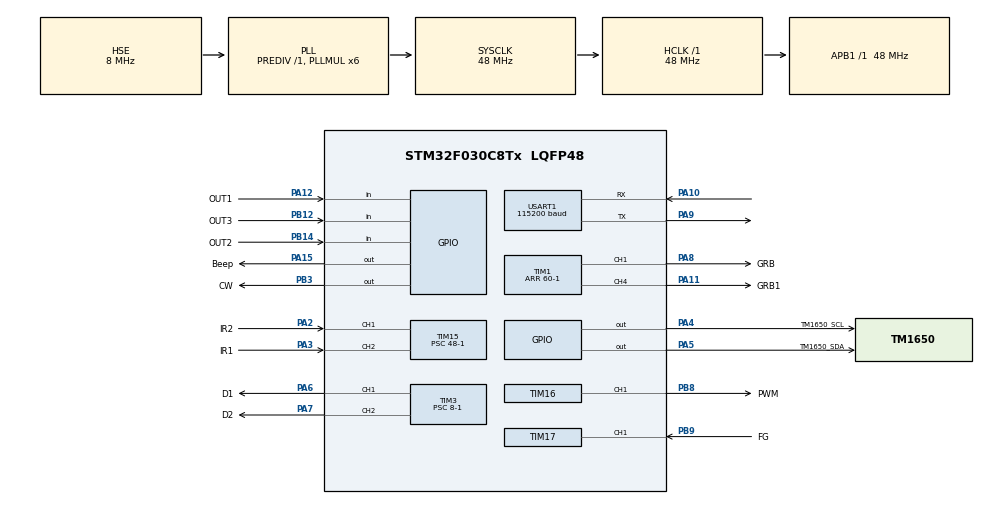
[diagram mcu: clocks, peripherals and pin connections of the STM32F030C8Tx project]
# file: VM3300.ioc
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Dma.Request0=TIM1_CH1
Dma.Request1=TIM1_CH4/TRIG/COM
Dma.TIM1_CH1.0.Direction=DMA_MEMORY_TO_PERIPH
Dma.TIM1_CH1.0.Instance=DMA1_Channel2
Dma.TIM1_CH1.0.MemDataAlignment=DMA_MDATAALIGN_HALFWORD
Dma.TIM1_CH1.0.MemInc=DMA_MINC_ENABLE
Dma.TIM1_CH1.0.Mode=DMA_NORMAL
Dma.TIM1_CH1.0.PeriphDataAlignment=DMA_PDATAALIGN_HALFWORD
Dma.TIM1_CH1.0.PeriphInc=DMA_PINC_DISABLE
Dma.TIM1_CH1.0.Priority=DMA_PRIORITY_MEDIUM
Dma.TIM1_CH4/TRIG/COM.1.Direction=DMA_MEMORY_TO_PERIPH
Dma.TIM1_CH4/TRIG/COM.1.Instance=DMA1_Channel4
Dma.TIM1_CH4/TRIG/COM.1.MemDataAlignment=DMA_MDATAALIGN_HALFWORD
Dma.TIM1_CH4/TRIG/COM.1.MemInc=DMA_MINC_ENABLE
Dma.TIM1_CH4/TRIG/COM.1.Mode=DMA_NORMAL
Dma.TIM1_CH4/TRIG/COM.1.PeriphDataAlignment=DMA_PDATAALIGN_HALFWORD
Dma.TIM1_CH4/TRIG/COM.1.PeriphInc=DMA_PINC_DISABLE
Dma.TIM1_CH4/TRIG/COM.1.Priority=DMA_PRIORITY_MEDIUM
Mcu.Family=STM32F0
Mcu.Name=STM32F030C8Tx
Mcu.Package=LQFP48
NVIC.DMA1_Channel2_3_IRQn=true\:0\:0\:false\:false\:true\:false\:true\:true
NVIC.DMA1_Channel4_5_IRQn=true\:0\:0\:false\:false\:true\:false\:true\:true
NVIC.TIM15_IRQn=true\:0\:0\:true\:false\:true\:true\:true\:true
NVIC.TIM17_IRQn=true\:0\:0\:false\:false\:true\:true\:true\:true
NVIC.TIM6_IRQn=true\:0\:0\:false\:false\:true\:true\:true\:true
NVIC.USART1_IRQn=true\:1\:0\:true\:false\:true\:true\:true\:true
PA10.Mode=Asynchronous
PA10.Signal=USART1_RX
PA11.GPIO_Label=GRB1
PA11.Signal=S_TIM1_CH4
PA12.GPIO_Label=OUT1
PA12.Signal=GPIO_Input
PA13.Mode=Serial_Wire
PA13.Signal=SYS_SWDIO
PA14.Mode=Serial_Wire
PA14.Signal=SYS_SWCLK
PA15.GPIO_Label=Beep
PA15.Signal=GPIO_Output
PA2.GPIO_Label=IR2
PA2.Signal=S_TIM15_CH1
PA3.GPIO_Label=IR1
PA3.Signal=S_TIM15_CH2
PA4.GPIO_Label=TM1650_SCL
PA4.GPIO_PuPd=GPIO_PULLUP
PA4.GPIO_Speed=GPIO_SPEED_FREQ_HIGH
PA4.PinState=GPIO_PIN_SET
PA4.Signal=GPIO_Output
PA5.GPIO_Label=TM1650_SDA
PA5.GPIO_PuPd=GPIO_PULLUP
PA5.GPIO_Speed=GPIO_SPEED_FREQ_HIGH
PA5.PinState=GPIO_PIN_SET
PA5.Signal=GPIO_Output
PA6.GPIO_Label=D1
PA6.Signal=S_TIM3_CH1
PA7.GPIO_Label=D2
PA7.Signal=S_TIM3_CH2
PA8.GPIO_Label=GRB
PA8.Signal=S_TIM1_CH1
PA9.Mode=Asynchronous
PA9.Signal=USART1_TX
PB12.GPIO_Label=OUT3
PB12.Signal=GPIO_Input
PB14.GPIO_Label=OUT2
PB14.Signal=GPIO_Input
PB3.GPIO_Label=CW
PB3.Signal=GPIO_Output
PB8.GPIO_Label=PWM
PB8.Signal=S_TIM16_CH1
PB9.GPIO_Label=FG
PB9.Signal=S_TIM17_CH1
PF0-OSC_IN.Mode=HSE-External-Oscillator
PF0-OSC_IN.Signal=RCC_OSC_IN
PF1-OSC_OUT.Mode=HSE-External-Oscillator
PF1-OSC_OUT.Signal=RCC_OSC_OUT
ProjectManager.HeapSize=0x200
ProjectManager.StackSize=0x400
ProjectManager.TargetToolchain=MDK-ARM V5.32
RCC.AHBFreq_Value=48000000
RCC.APB1Freq_Value=48000000
RCC.APB1TimFreq_Value=48000000
RCC.HCLKFreq_Value=48000000
RCC.PLLMUL=RCC_PLL_MUL6
RCC.PLLSourceVirtual=RCC_PLLSOURCE_HSE
RCC.SYSCLKFreq_VALUE=48000000
RCC.SYSCLKSource=RCC_SYSCLKSOURCE_PLLCLK
SH.S_TIM15_CH1.0=TIM15_CH1,Input_Capture1_from_TI1
SH.S_TIM15_CH2.0=TIM15_CH2,Input_Capture2_from_TI2
SH.S_TIM16_CH1.0=TIM16_CH1,PWM Generation1 CH1
SH.S_TIM17_CH1.0=TIM17_CH1,Input_Capture1_from_TI1
SH.S_TIM1_CH1.0=TIM1_CH1,PWM Generation1 CH1
SH.S_TIM1_CH4.0=TIM1_CH4,PWM Generation4 CH4
SH.S_TIM3_CH1.0=TIM3_CH1,PWM Generation1 CH1
SH.S_TIM3_CH2.0=TIM3_CH2,PWM Generation2 CH2
TIM1.Channel-PWM\ Generation1\ CH1=TIM_CHANNEL_1
TIM1.Channel-PWM\ Generation4\ CH4=TIM_CHANNEL_4
TIM1.Period=60-1
TIM1.Pulse-PWM\ Generation1\ CH1=0
TIM1.Pulse-PWM\ Generation4\ CH4=0
TIM15.Channel-Input_Capture1_from_TI1=TIM_CHANNEL_1
TIM15.Channel-Input_Capture2_from_TI2=TIM_CHANNEL_2
TIM15.ICPolarity_CH1=TIM_INPUTCHANNELPOLARITY_RISING
TIM15.ICPolarity_CH2=TIM_INPUTCHANNELPOLARITY_RISING
TIM15.Period=10000
TIM15.Prescaler=48-1
TIM16.Channel=TIM_CHANNEL_1
TIM16.OCPolarity_1=TIM_OCPOLARITY_HIGH
TIM16.Period=200-1
TIM16.Prescaler=12-1
TIM17.Channel=TIM_CHANNEL_1
TIM17.Prescaler=4800-1
TIM3.Channel-PWM\ Generation1\ CH1=TIM_CHANNEL_1
TIM3.Channel-PWM\ Generation2\ CH2=TIM_CHANNEL_2
TIM3.Period=158-1
TIM3.Prescaler=8-1
TIM6.AutoReloadPreload=TIM_AUTORELOAD_PRELOAD_DISABLE
TIM6.Period=10-1
TIM6.Prescaler=48-1
USART1.BaudRate=115200
USART1.VirtualMode-Asynchronous=VM_ASYNC
VP_TIM15_VS_ClockSourceINT.Mode=Internal
VP_TIM16_VS_ClockSourceINT.Mode=Enable_Timer
VP_TIM17_VS_ClockSourceINT.Mode=Enable_Timer
VP_TIM6_VS_ClockSourceINT.Mode=Enable_Timer
board=custom

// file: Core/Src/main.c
/* USER CODE BEGIN Header */
/**
  ******************************************************************************
  * @file           : main.c
  * @brief          : Main program body
  ******************************************************************************
  * @attention
  *
  * Copyright (c) 2024 STMicroelectronics.
  * All rights reserved.
  *
  * This software is licensed under terms that can be found in the LICENSE file
  * in the root directory of this software component.
  * If no LICENSE file comes with this software, it is provided AS-IS.
  *
  ******************************************************************************
  */
/* USER CODE END Header */
#include "main.h"
#include "dma.h"
#include "tim.h"
#include "usart.h"
#include "gpio.h"

void SystemClock_Config(void);

int main(void)
{

  /* MCU Configuration--------------------------------------------------------*/

  /* Reset of all peripherals, Initializes the Flash interface and the Systick. */
  HAL_Init();

  /* Configure the system clock */
  SystemClock_Config();

  /* Initialize all configured peripherals */
  MX_GPIO_Init();
  MX_DMA_Init();
  MX_TIM1_Init();
  MX_TIM3_Init();
  MX_TIM15_Init();
  MX_TIM16_Init();
  MX_USART1_UART_Init();
  MX_TIM17_Init();
  MX_TIM6_Init();
  /* USER CODE BEGIN 2 */
	System_Init();//ϵͳ������ʼ��
  /* USER CODE END 2 */

  /* Infinite loop */
  /* USER CODE BEGIN WHILE */
  while (1)
  {
      NEC_Send(0x00,0x19,0);
    /* USER CODE END WHILE */

  }
}

void SystemClock_Config(void)
{
  RCC_OscInitTypeDef RCC_OscInitStruct = {0};
  RCC_ClkInitTypeDef RCC_ClkInitStruct = {0};
  RCC_PeriphCLKInitTypeDef PeriphClkInit = {0};

  /** Initializes the RCC Oscillators according to the specified parameters
  * in the RCC_OscInitTypeDef structure.
  */
  RCC_OscInitStruct.OscillatorType = RCC_OSCILLATORTYPE_HSE;
  RCC_OscInitStruct.HSEState = RCC_HSE_ON;
  RCC_OscInitStruct.PLL.PLLState = RCC_PLL_ON;
  RCC_OscInitStruct.PLL.PLLSource = RCC_PLLSOURCE_HSE;
  RCC_OscInitStruct.PLL.PLLMUL = RCC_PLL_MUL6;
  RCC_OscInitStruct.PLL.PREDIV = RCC_PREDIV_DIV1;
  if (HAL_RCC_OscConfig(&RCC_OscInitStruct) != HAL_OK)
  {
    Error_Handler();
  }

  /** Initializes the CPU, AHB and APB buses clocks
  */
  RCC_ClkInitStruct.ClockType = RCC_CLOCKTYPE_HCLK|RCC_CLOCKTYPE_SYSCLK
                              |RCC_CLOCKTYPE_PCLK1;
  RCC_ClkInitStruct.SYSCLKSource = RCC_SYSCLKSOURCE_PLLCLK;
  RCC_ClkInitStruct.AHBCLKDivider = RCC_SYSCLK_DIV1;
  RCC_ClkInitStruct.APB1CLKDivider = RCC_HCLK_DIV1;

  if (HAL_RCC_ClockConfig(&RCC_ClkInitStruct, FLASH_LATENCY_1) != HAL_OK)
  {
    Error_Handler();
  }
  PeriphClkInit.PeriphClockSelection = RCC_PERIPHCLK_USART1;
  PeriphClkInit.Usart1ClockSelection = RCC_USART1CLKSOURCE_PCLK1;
  if (HAL_RCCEx_PeriphCLKConfig(&PeriphClkInit) != HAL_OK)
  {
    Error_Handler();
  }
}

void Error_Handler(void)
{
  __disable_irq();
  while (1)
  {
  }
}
